# nrf9230_enga_application register map
Vendor: Nordic Semiconductor; Series: nRF92; File version: 1
CPU: CM33 r0p4, little endian, MPU, FPU, 3 interrupt priority bits, 480 interrupts, 4 SAU regions
Registers are 32-bit, read-write, reset 0x0 unless marked. A register's access mark holds for its fields unless they carry their own. Offsets are from the block's base; [hi:lo] are bit positions; {n}, {i} and the like mark numbered series; 'fields as' and 'values as' point back to an identical list.

## GLOBAL_MIPIRFFE_NS — MipiRffe Master 0
Base 0x4F99B000
Same registers: GLOBAL_MIPIRFFE_S 0x5F99B000
0x00 TASKS_START wo — MipiRffe transmission start trigger
  [0] TASKS_START
    1=Trigger task
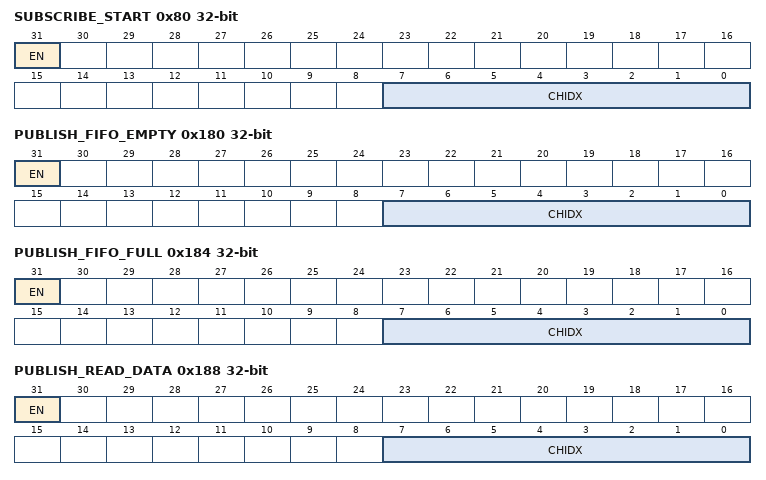
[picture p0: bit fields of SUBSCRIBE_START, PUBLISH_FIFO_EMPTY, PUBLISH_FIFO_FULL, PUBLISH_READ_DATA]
0x80 SUBSCRIBE_START — Subscribe configuration for task START
  [31] EN
    0=Disabled (Disable subscription); 1=Enabled (Enable subscription)
  [7:0] CHIDX — DPPI channel that task START will subscribe to
0x100 EVENTS_FIFO_EMPTY — Fifo empty after transmission started
  [0] EVENTS_FIFO_EMPTY
    0=NotGenerated (Event not generated); 1=Generated (Event generated)
0x104 EVENTS_FIFO_FULL — Fifo full event
  [0] EVENTS_FIFO_FULL
    values as EVENTS_FIFO_EMPTY.EVENTS_FIFO_EMPTY
0x108 EVENTS_READ_DATA — Mipi RF front-end bus read data available in register
  [0] EVENTS_READ_DATA
    values as EVENTS_FIFO_EMPTY.EVENTS_FIFO_EMPTY
0x10C EVENTS_READ_PARITY — Mipi RF front-end bus read data parity error
  [0] EVENTS_READ_PARITY
    values as EVENTS_FIFO_EMPTY.EVENTS_FIFO_EMPTY
0x110 EVENTS_NO_RESPONSE — Mipi RF front-end bus slave returned no response frame
  [0] EVENTS_NO_RESPONSE
    values as EVENTS_FIFO_EMPTY.EVENTS_FIFO_EMPTY
0x114 EVENTS_READ_OVERWRITE — Unread Mipi RF front-end bus read data overwritten
  [0] EVENTS_READ_OVERWRITE
    values as EVENTS_FIFO_EMPTY.EVENTS_FIFO_EMPTY
0x118 EVENTS_FIFO_OVERFLOW — FIFO overflow occured
  [0] EVENTS_FIFO_OVERFLOW
    values as EVENTS_FIFO_EMPTY.EVENTS_FIFO_EMPTY
0x180 PUBLISH_FIFO_EMPTY — Publish configuration for event FIFO_EMPTY
  [31] EN
    0=Disabled (Disable publishing); 1=Enabled (Enable publishing)
  [7:0] CHIDX — DPPI channel that event FIFO_EMPTY will publish to
0x184 PUBLISH_FIFO_FULL — Publish configuration for event FIFO_FULL
  [31] EN
    values as PUBLISH_FIFO_EMPTY.EN
  [7:0] CHIDX — DPPI channel that event FIFO_FULL will publish to
0x188 PUBLISH_READ_DATA — Publish configuration for event READ_DATA
  [31] EN
    values as PUBLISH_FIFO_EMPTY.EN
  [7:0] CHIDX — DPPI channel that event READ_DATA will publish to
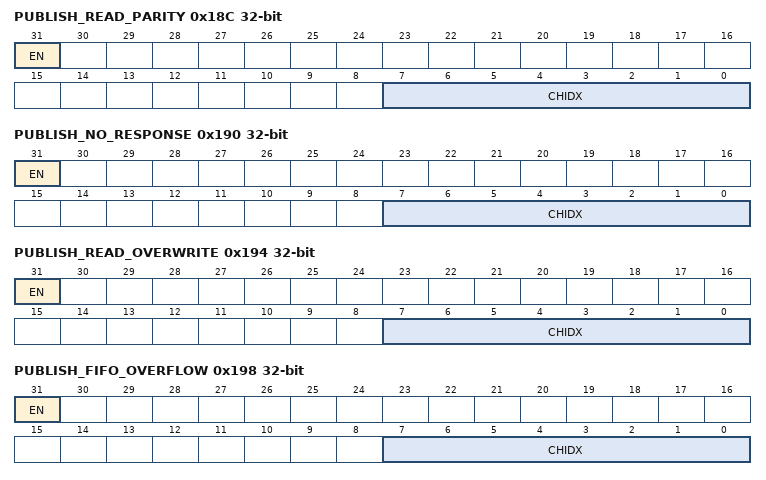
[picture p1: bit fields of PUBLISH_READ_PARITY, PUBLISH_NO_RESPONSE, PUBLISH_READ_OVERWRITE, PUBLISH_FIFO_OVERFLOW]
0x18C PUBLISH_READ_PARITY — Publish configuration for event READ_PARITY
  [31] EN
    values as PUBLISH_FIFO_EMPTY.EN
  [7:0] CHIDX — DPPI channel that event READ_PARITY will publish to
0x190 PUBLISH_NO_RESPONSE — Publish configuration for event NO_RESPONSE
  [31] EN
    values as PUBLISH_FIFO_EMPTY.EN
  [7:0] CHIDX — DPPI channel that event NO_RESPONSE will publish to
0x194 PUBLISH_READ_OVERWRITE — Publish configuration for event READ_OVERWRITE
  [31] EN
    values as PUBLISH_FIFO_EMPTY.EN
  [7:0] CHIDX — DPPI channel that event READ_OVERWRITE will publish to
0x198 PUBLISH_FIFO_OVERFLOW — Publish configuration for event FIFO_OVERFLOW
  [31] EN
    values as PUBLISH_FIFO_EMPTY.EN
  [7:0] CHIDX — DPPI channel that event FIFO_OVERFLOW will publish to
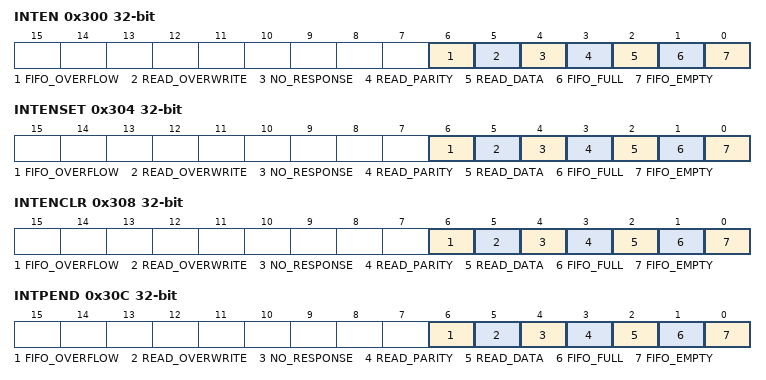
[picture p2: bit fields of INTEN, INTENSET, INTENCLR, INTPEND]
0x300 INTEN — Enable or disable interrupt
  [all] fields
    0=Disabled; 1=Enabled
  [6] FIFO_OVERFLOW — Enable or disable interrupt for event FIFO_OVERFLOW
  [5] READ_OVERWRITE — Enable or disable interrupt for event READ_OVERWRITE
  [4] NO_RESPONSE — Enable or disable interrupt for event NO_RESPONSE
  [3] READ_PARITY — Enable or disable interrupt for event READ_PARITY
  [2] READ_DATA — Enable or disable interrupt for event READ_DATA
  [1] FIFO_FULL — Enable or disable interrupt for event FIFO_FULL
  [0] FIFO_EMPTY — Enable or disable interrupt for event FIFO_EMPTY
0x304 INTENSET — Enable interrupt
  [all] fields
    on read: 0=Disabled (Read: Disabled); 1=Enabled (Read: Enabled) | on write: 1=Set (Enable)
  [6] FIFO_OVERFLOW — Write '1' to enable interrupt for event FIFO_OVERFLOW
  [5] READ_OVERWRITE — Write '1' to enable interrupt for event READ_OVERWRITE
  [4] NO_RESPONSE — Write '1' to enable interrupt for event NO_RESPONSE
  [3] READ_PARITY — Write '1' to enable interrupt for event READ_PARITY
  [2] READ_DATA — Write '1' to enable interrupt for event READ_DATA
  [1] FIFO_FULL — Write '1' to enable interrupt for event FIFO_FULL
  [0] FIFO_EMPTY — Write '1' to enable interrupt for event FIFO_EMPTY
0x308 INTENCLR — Disable interrupt
  [all] fields
    on read: 0=Disabled (Read: Disabled); 1=Enabled (Read: Enabled) | on write: 1=Clear (Disable)
  [6] FIFO_OVERFLOW — Write '1' to disable interrupt for event FIFO_OVERFLOW
  [5] READ_OVERWRITE — Write '1' to disable interrupt for event READ_OVERWRITE
  [4] NO_RESPONSE — Write '1' to disable interrupt for event NO_RESPONSE
  [3] READ_PARITY — Write '1' to disable interrupt for event READ_PARITY
  [2] READ_DATA — Write '1' to disable interrupt for event READ_DATA
  [1] FIFO_FULL — Write '1' to disable interrupt for event FIFO_FULL
  [0] FIFO_EMPTY — Write '1' to disable interrupt for event FIFO_EMPTY
0x30C INTPEND ro — Pending interrupts
  [all] fields
    on read: 0=NotPending (Read: Not pending); 1=Pending (Read: Pending)
  [6] FIFO_OVERFLOW — Read pending status of interrupt for event FIFO_OVERFLOW
  [5] READ_OVERWRITE — Read pending status of interrupt for event READ_OVERWRITE
  [4] NO_RESPONSE — Read pending status of interrupt for event NO_RESPONSE
  [3] READ_PARITY — Read pending status of interrupt for event READ_PARITY
  [2] READ_DATA — Read pending status of interrupt for event READ_DATA
  [1] FIFO_FULL — Read pending status of interrupt for event FIFO_FULL
  [0] FIFO_EMPTY — Read pending status of interrupt for event FIFO_EMPTY
0x400 READ_DATA ro — Read data received from Mipi RF front-end bus
  [31:0] DATA — read data bytes received from Mipi RF front-end bus slave, starting from [7:0]. Unused bytes are all zero.
0x404 RFFE_STATUS ro — Current state of RFFE state machine
  [3:0] STATUS — RFFE status. Encoding specified in specification
    0=IDLE (Rffe bus in idle state, clock and data driven actively low); 1=SSC1 (Rffe bus in first start sequence cycle (data high, clock low)); 2=SSC0 (Rffe bus in second start sequence cycle (data low, clock low)); 3=COMMAND_FRAME (Master is providing command frame to slave); 4=COMMAND_PARITY (Master is providing command frame parity bit); 5=WRITE_BYTE (Sdata and sclk driven by master); 6=WRITE_PARITY (Master is providing parity bit); 7=BUSPARK_0 (Buspark after write operation); 8=BUSPARK_1 (Master is releasing sdata for slave between command frame and read bytes); 9=READ_BYTE (slave is driving data on sdata, sclk in read mode driven by master); 10=READ_PARITY (slave providing parity bit); 11=BUSPARK_END (Buspark after read operation, sdata controlled by slave, clock driven); 12=BUSPARK_SILENT (Silent Buspark at the end of synchronous read, sdata driven to low by master, clock is not driven)
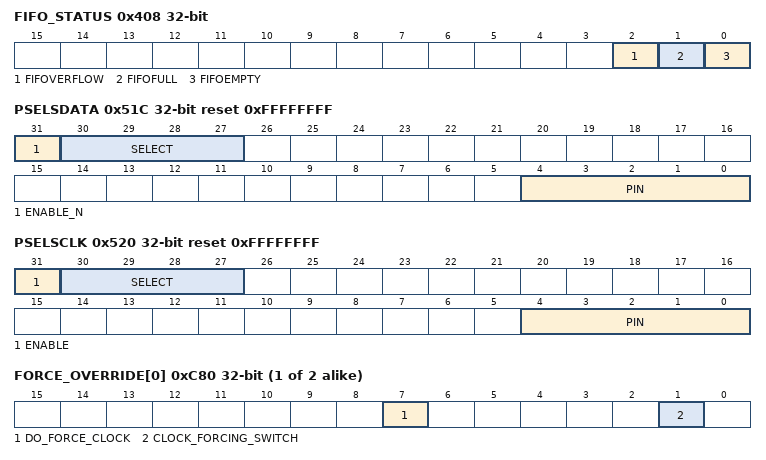
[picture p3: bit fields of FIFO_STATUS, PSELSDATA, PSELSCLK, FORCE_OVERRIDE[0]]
0x408 FIFO_STATUS ro — Status of FIFO
  [2] FIFOVERFLOW — FIFO empty indication
    0=NoOverflow (FIFO overflow has not occured); 1=Overflow (FIFO overflow has occured)
  [1] FIFOFULL — FIFO full indication
    0=NotFull (FIFO is not full); 1=Full (FIFO is full)
  [0] FIFOEMPTY — FIFO empty indication
    0=NotEmpty (FIFO is not empty); 1=Empty (FIFO is empty)
0x500 MIPIRFFE_ENABLE — MipiRffe IP enable
  [0] ENABLE — Enable bit for MipiRffe IP
    0=Disabled; 1=Enabled
0x504 FRAME_COMMAND — Command part of MipiRffe transaction. (See digip_401 Design Description table 4. Supported Frame types pg. 13)
  [11:0] COMMAND — MipiRffe transaction command
0x508 FRAME_ADDRESS — Address part of MipiRffe transaction
  [15:0] ADDRESS — Address in case of extended long access. In case of extended access, the LSB byte is used as address and MSB byte discarded. Ignored for other frame types.
0x50C FRAME_DATA — Data bytes of MipiRffe transaction
  [31:0] DATA — MipiRffe transaction data bytes, 0 to 4 bytes depending on frame type and command frame value. First byte in bits [7:0].
0x510 DIVIDER — MipiRffe transceiver and bus clock divider config
  [1:0] DIVIDER — Division setting from ckCore to SCLK and transceiver logic
    0=Div4 (Division by 4); 1=Div8 (Division by 8); 2=Div16 (Division by 16); 3=Div6 (Division by 6)
0x514 READMODE_DIVIDER — MipiRffe transceiver and bus clock readmode divider config
  [1:0] READMODE_DIVIDER — Only used in read mode to slow down clock for slave, further dividing ckCore (on top of DIVIDER setting). Used when slave cannot provide data output in full speed.
    0=Undivided; 1=Div2 (Division by 2); 2=Div4 (Division by 4); 3=Div8 (Division by 8)
0x518 MIPIRFFE_FTM — Functional test mode enable register
  [0] ENABLE — Functional test mode enable
    0=Normal_mode; 1=Functional_test_mode
0x51C PSELSDATA reset 0xFFFFFFFF — Pin select register for SDATA pad
  [31] ENABLE_N — SDATA pin enable
    0=Enabled; 1=Disabled
  [30:27] SELECT — SDATA pin select value for mode. (Not used in LynxRf.)
  [4:0] PIN — SDATA pin number, from 0 to 31. (Not used in LynxRf. SDATA is mapped to RFGPIO4.)
0x520 PSELSCLK reset 0xFFFFFFFF — Pin select register for SCLK pad
  [31] ENABLE — SCLK pin enable
    0=Enabled; 1=Disabled
  [30:27] SELECT — SCLK pin select value for mode. (Not used in LynxRf.)
  [4:0] PIN — SCLK pin number, from 0 to 31. (Not used in LynxRf. SCLK is mapped to RFGPIO3.)
0x524 SREADMODE — Synchronous read enable
  [0] SREADENABLE — Enable bit for synchronous read
    0=Disabled; 1=Enabled
0xC04 PENALTY_REG_1 reset 0xFFFFFFFC — Penalty register for PCP 1.
  [1:0] PENALTY — Penalty level.
    0=Full ((Auto 0) Full penalty); 1=Semi0 ((Auto 1) Semi (power on, clock off)); 2=Semi1 ((Auto 2) Semi (power on, clock core on, clock buffer off)); 3=Zero ((Auto 3) Zero penalty)
{0xC80+4i} FORCE_OVERRIDE[{i}] (i=0..1) — Description collection: Force override register for PCP n.
  [7] DO_FORCE_CLOCK — Enable/disable forcing of the clock request signals.
    0=Disabled; 1=Enabled
  [1] CLOCK_FORCING_SWITCH — See DO_FORCE_CLOCK.
    0=Zero (clockRequest.switch = 0); 1=One (clockRequest.switch = 1)
